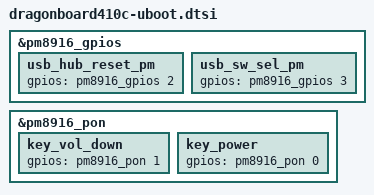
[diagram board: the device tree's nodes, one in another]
/*
 * U-Boot addition to handle Dragonboard 410c pins
 *
 * (C) Copyright 2015 Mateusz Kulikowski <mateusz.kulikowski@gmail.com>
 *
 * SPDX-License-Identifier:	GPL-2.0+
 */

&pm8916_gpios {
	usb_hub_reset_pm {
		gpios = <&pm8916_gpios 2 0>;
	};

	usb_sw_sel_pm {
		gpios = <&pm8916_gpios 3 0>;
	};
};


&pm8916_pon {
	key_vol_down {
		gpios = <&pm8916_pon 1 0>;
	};

	key_power {
		gpios = <&pm8916_pon 0 0>;
	};
};
